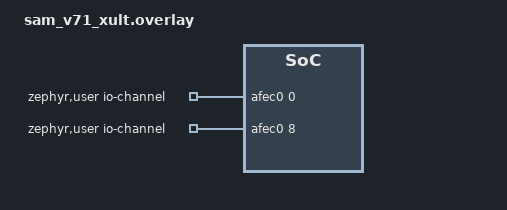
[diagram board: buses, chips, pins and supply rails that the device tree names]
/*
 * SPDX-License-Identifier: Apache-2.0
 *
 * Copyright (c) 2022, Gerson Fernando Budke
 */

/ {
	zephyr,user {
		/* adjust channel number according to pinmux in board.dts */
		io-channels = <&afec0 0>, <&afec0 8>;
	};
};
